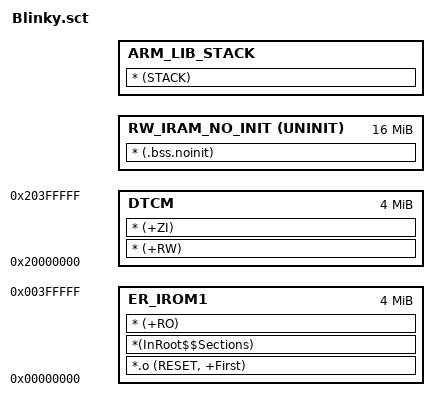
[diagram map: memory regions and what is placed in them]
#! armcc -E

#define DTCM_SIZE               0x00400000
#define STACK_SIZE              (DTCM_SIZE - ImageLength(DTCM))

#define PRAM_SIZE               0x01000000
#define HEAP_SIZE               (PRAM_SIZE - ImageLength(RW_IRAM_NO_INIT) - ImageLength(RW_IRAM_BSS))
; *************************************************************
; *** Scatter-Loading Description File generated by uVision ***
; *************************************************************

LR_IROM1 0x00000000 0x00400000  {    ; load region size_region
    ER_IROM1 0x00000000 0x00400000  {  ; load address = execution address
    *.o (RESET, +First)
    *(InRoot$$Sections)
    * (+RO)
    }
    
    DTCM 0x20000000 DTCM_SIZE  {  ; RW data
        * (+RW)
        * (+ZI)
    }
    RW_IRAM_NO_INIT +0 UNINIT PRAM_SIZE {
      * (.bss.noinit)
    }
    ARM_LIB_STACK +0   {
        * (STACK)
    }
    
    /*
    RW_IRAM_BSS 0x60000000 PRAM_SIZE {
      * (+ZI)
    }
    RW_IRAM_NO_INIT +0 UNINIT PRAM_SIZE {
      * (.bss.noinit)
    }
    ARM_LIB_HEAP  +0 ALIGN 64 HEAP_SIZE {
        * (HEAP)
    }
    */
}

